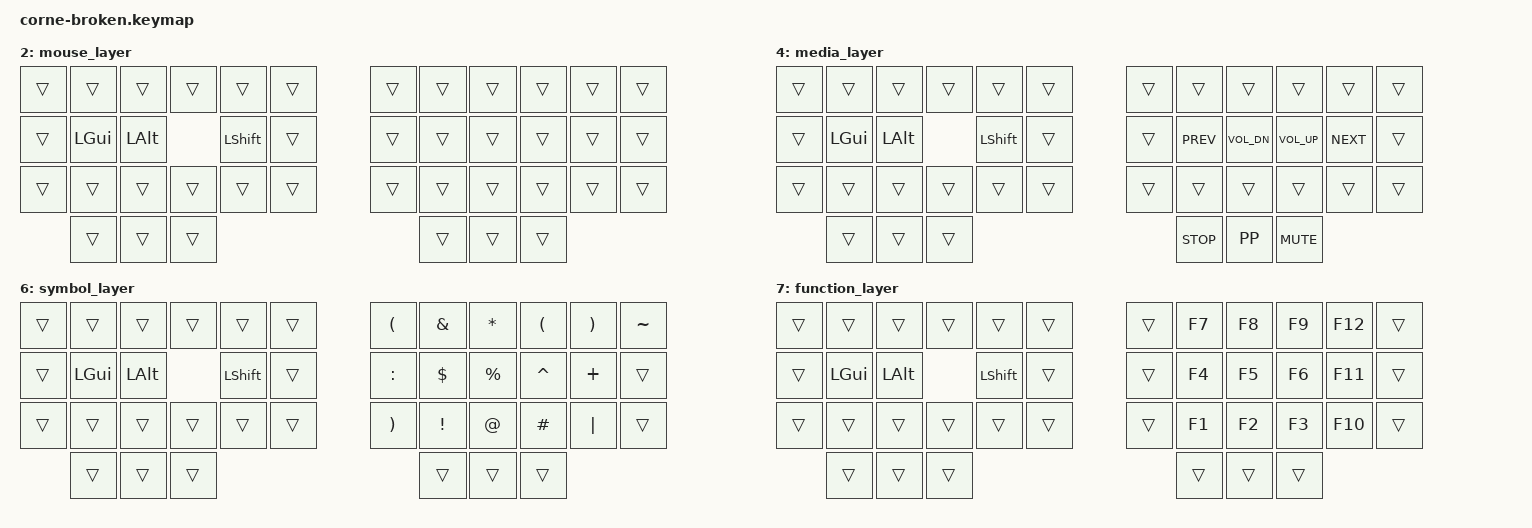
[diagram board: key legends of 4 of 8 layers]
/*
 * Copyright (c) 2020 The ZMK Contributors
 *
 * SPDX-License-Identifier: MIT
 */

#include <behaviors.dtsi>
#include <dt-bindings/zmk/keys.h>
#include <dt-bindings/zmk/bt.h>
#include <dt-bindings/zmk/outputs.h>
#include <dt-bindings/zmk/rgb.h>


// layer mappings:
#define NAV_LYR 1
#define MSE_LYR 2
#define BUT_LYR 3
#define MED_LYR 4
#define NUM_LYR 5
#define SYM_LYR 6
#define FUN_LYR 7

/ {
        keymap {
                compatible = "zmk,keymap";

default_layer {
// -----------------------------------------------------------------------------------------
//  | ESC |  Q  |  W  |  E  |  R  |  T  |   |  Y  |  U   |  I  |  O  |  P  |BSPC |
//  | TAB |  A  |  S  |  D  |  F  |  G  |   |  H  |  J   |  K  |  L  |  ;  |  '  |
//  | SHFT|  Z  |  X  |  C  |  V  |  B  |   |  N  |  M   |  ,  |  .  |  /  | ESC |
//                    | GUI | SPC | TAB |   | ENT | BSPC | DEL |
//                    | GUI | NAV | MSE |   | SYM | NUM  | FUN |
    bindings = <
        &kp TAB   &kp Q &kp W &kp E &kp R &kp T         &kp Y &kp U  &kp I     &kp O   &kp P    &kp BSPC
        &kp LCTRL &kp A &kp S &kp D &kp F &kp G         &kp H &kp J  &kp K     &kp L   &kp SEMI &kp SQT
        &kp LSHFT &kp Z &kp X &kp C &kp V &kp B         &kp N &kp M  &kp COMMA &kp DOT &kp FSLH &kp ESC
        &kp LGUI &lt NAV_LYR SPACE &lt MSE_LYR TAB      &lt SYM_LYR RETURN &lt NUM_LYR BSPC &lt FUN_LYR DEL
    >;
};

nav_layer {
// -----------------------------------------------------------------------------------------
// |     |     |     |     |     |     |   |REDO |PSTE | CPY | CUT |UNDO |     |
// |     | WIN | ALT |CTRL |SHFT |     |   |CAPS | LFT | DWN |  UP | RGT |     |
// |     |     |     |     |     |     |   | INS |HOME |PGDN |PGUP | END |     |
//                   |     |     |     |   | ENT |     | ALT |
    bindings = <
        &trans &trans &trans &trans &trans &trans           &trans &trans &trans &trans &trans &trans
        &trans &kp LGUI &kp LALT &kp LSHFT &trans           &kp CAPS &kp LEFT &kp DOWN &kp UP &kp RIGHT
        &trans &trans &trans &trans &trans &trans           &trans &kp HOME &kp PG_DN &kp PG_UP &kp END
                &trans &trans &trans                                &kp ENTER &trans &kp RALT
    >;
};

// TODO:
mouse_layer {
// -----------------------------------------------------------------------------------------
// |     |     |     |     |     |     |   |     |REDO |PSTE | CPY | CUT |UNDO |
// |     | WIN | ALT |CTRL |SHFT |     |   |     | LFT | DWN |  UP | RGT |     |
// |     |     |     |     |     |     |   |     | LFT | DWN |  UP | RGT |     |
//                   |     |     |     |   | M1  | M3  | M2  |
    bindings = <
        &trans &trans &trans &trans &trans &trans           &trans &trans &trans &trans &trans &trans
        &trans &kp LGUI &kp LALT &kp LSHFT &trans           &trans &trans &trans &trans &trans &trans
        &trans &trans &trans &trans &trans &trans           &trans &trans &trans &trans &trans &trans
                &trans &trans &trans                                &trans &trans &trans
    >;
};




button_layer {
// -----------------------------------------------------------------------------------------
// |     |     |     |     |     |     |   |     |     |     |     |     |     |
// |     |     |     |     |     |     |   |     |     |     |     |     |     |
// |     |     |     |     |     |     |   |     |     |     |     |     |     |
//                   |     |     |     |   |     |     |     |
    bindings = <
        &trans &trans &trans &trans &trans &trans           &trans &trans &trans &trans &trans &trans
        &trans &trans &trans &trans &trans &trans           &trans &trans &trans &trans &trans &trans
        &trans &trans &trans &trans &trans &trans           &trans &trans &trans &trans &trans &trans
                &trans &trans &trans                                &trans &trans &trans
    >;
};

media_layer {
// -----------------------------------------------------------------------------------------
// |     |     |     |     |     |     |   |     |     |     |     |     |     |
// |     | WIN | ALT |CTRL |SHFT |     |   |     |     |PREV |VO_DN|VO_UP|NEXT |
// |     |     |     |     |     |     |   |     |     |     |     |     |     |
//                   |     |     |     |   |     |STOP |PL/PA|MUTE |
    bindings = <
        &trans &trans &trans &trans &trans &trans               &trans &trans &trans &trans &trans &trans
        &trans &kp LGUI &kp LALT &kp LSHFT &trans               &trans &kp K_PREV &kp K_VOL_DN &kp K_VOL_UP &kp K_NEXT &trans
        &trans &trans &trans &trans &trans &trans               &trans &trans &trans &trans &trans &trans
                &trans &trans &trans                                &kp K_STOP &kp K_PP &kp K_MUTE
    >;
};




// swapped / mirrored from original layout:



number_layer {
// -----------------------------------------------------------------------------------------
// |     |     |     |     |     |     |   | [{  |  7  |  8  |  9  | ]}  | `~  |
// |     | WIN | ALT |CTRL |SHFT |     |   | ;:  |  4  |  5  |  6  | =+  |     |
// |     |     |     |     |     |     |   | 0)  |  1  |  2  |  3  | \|  |     |
//                   |     |     |     |   |     |     |     |
    bindings = <
        &trans &trans &trans &trans &trans &trans           &kp LBKT &kp NUMBER_7 &kp NUMBER_8 &kp NUMBER_9 &kp RBKT &kp GRAVE
        &trans &kp LGUI &kp LALT &kp LSHFT &trans           &kp SEMI &kp NUMBER_4 &kp NUMBER_5 &kp NUMBER_6 &kp EQUAL &trans
        &trans &trans &trans &trans &trans &trans           &kp NUMBER_0 &kp NUMBER_1 &kp &kp NUMBER_2 &kp NUMBER_3 &kp BSLH &trans
                &trans &trans &trans                                &trans &trans &trans
    >;
};









symbol_layer {
// -----------------------------------------------------------------------------------------
// |     |     |     |     |     |     |   |  (  |  &  |  *  |  (  |  )  |  ~  |
// |     | WIN | ALT |CTRL |SHFT |     |   |  :  |  $  |  %  |  ^  |  +  |     |
// |     |     |     |     |     |     |   |  )  |  !  |  @  |  #  | "|" |     |
//                   |     |     |     |   |     |     |     |
    bindings = <
        &trans &trans &trans &trans &trans &trans           &kp LPAR &kp AMPS &kp ASTRK &kp LPAR &kp RPAR &kp TILDE
        &trans &kp LGUI &kp LALT &kp LSHFT &trans           &kp COLON &kp DOLLAR &kp PERCENT &kp CARET &kp PLUS &trans
        &trans &trans &trans &trans &trans &trans           &kp RPAR &kp EXCL &kp AT &kp HASH &kp PIPE &trans
                &trans &trans &trans                                &trans &trans &trans
    >;
};


function_layer {
// -----------------------------------------------------------------------------------------
// |     |     |     |     |     |     |   |     | F7  | F8  | F9  | F12 |     |
// |     | WIN | ALT |CTRL |SHFT |     |   |     | F4  | F5  | F6  | F11 |     |
// |     |     |     |     |     |     |   |     | F1  | F2  | F3  | F10 |     |
//                   |     |     |     |   |     |     |     |
    bindings = <
        &trans &trans &trans &trans &trans &trans           &trans &kp F7 &kp F8 &kp F9 &kp F12 &trans
        &trans &kp LGUI &kp LALT &kp LSHFT &trans           &trans &kp F4 &kp F5 &kp F6 &kp F11 &trans
        &trans &trans &trans &trans &trans &trans           &trans &kp F1 &kp F2 &kp F3 &kp F10 &trans
                &trans &trans &trans                                &trans &trans &trans
    >;
};


        };
};



                
